# STM32U585xx register map
File version: 1.0
Registers are 32-bit, read-write, reset 0x0 unless marked. A register's access mark holds for its fields unless they carry their own. Offsets are from the block's base; [hi:lo] are bit positions; {n}, {i} and the like mark numbered series; 'fields as' and 'values as' point back to an identical list.

## RNG
Base 0x420C0800
Same registers: RNG_S 0x520C0800
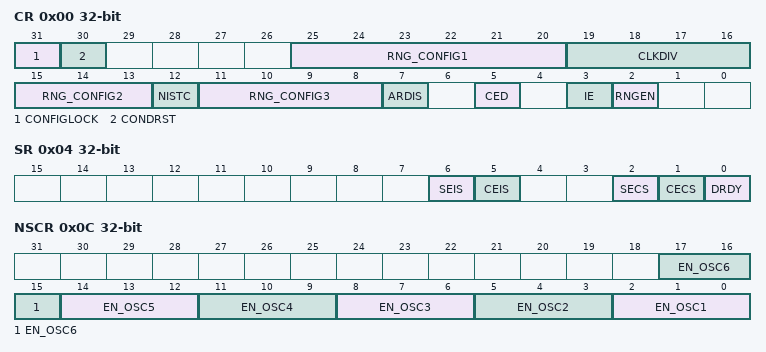
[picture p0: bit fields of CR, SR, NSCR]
0x00 CR — RNG control register
  [31] CONFIGLOCK
  [30] CONDRST
  [25:20] RNG_CONFIG1
  [19:16] CLKDIV
    0=BY_1 (No clock division); 1=BY_2 (2 RNG clock cycles per internal RNG clock); 2=BY_4 (4 RNG clock cycles per internal RNG clock); 3=BY_8 (8 RNG clock cycles per internal RNG clock); 4=BY_16 (16 RNG clock cycles per internal RNG clock); 5=BY_32 (32 RNG clock cycles per internal RNG clock); 6=BY_64 (64 RNG clock cycles per internal RNG clock); 7=BY_128 (128 RNG clock cycles per internal RNG clock); 8=BY_256 (256 RNG clock cycles per internal RNG clock); 9=BY_512 (512 RNG clock cycles per internal RNG clock); 10=BY_1024 (1024 RNG clock cycles per internal RNG clock); 11=BY_2048 (2048 RNG clock cycles per internal RNG clock); 12=BY_4096 (4096 RNG clock cycles per internal RNG clock); 13=BY_8192 (8192 RNG clock cycles per internal RNG clock); 14=BY_16384 (16384 RNG clock cycles per internal RNG clock); 15=BY_32768 (32768 RNG clock cycles per internal RNG clock)
  [15:13] RNG_CONFIG2
  [12] NISTC
  [11:8] RNG_CONFIG3
  [7] ARDIS
  [5] CED
  [3] IE
  [2] RNGEN
0x04 SR — RNG status register
  [6] SEIS, [5] CEIS, [2] SECS, [1] CECS, [0] DRDY
0x08 DR — RNG data register
0x0C NSCR — RNG noise source control register
  [3n-1:3n-3] EN_OSC{n} (n=1..6)
0x10 HTCR — RNG health test configuration register
  [31:0] HTCFG

## PKA
Base 0x420C2000
Same registers: PKA_S 0x520C2000
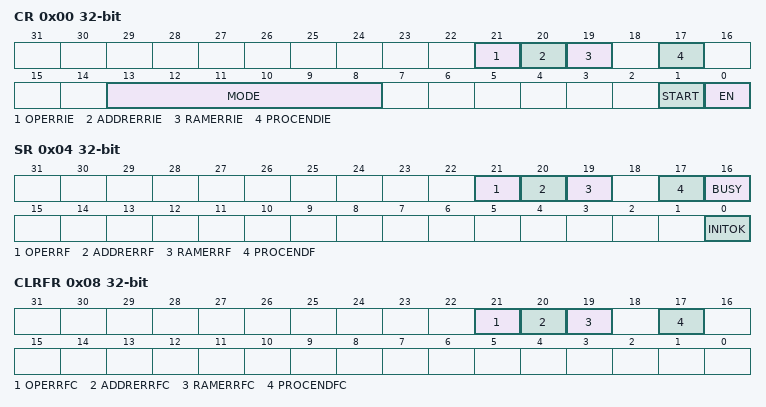
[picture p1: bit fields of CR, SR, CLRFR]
0x00 CR — PKA control register
  [21] OPERRIE — Operation Error interrupt enable
  [20] ADDRERRIE — Address error interrupt enable
  [19] RAMERRIE — RAM error interrupt enable
  [17] PROCENDIE — End of operation interrupt enable
  [13:8] MODE — MODE[5:0] PKA operation code
  [1] START — Start operation
  [0] EN — PKA enable
0x04 SR — PKA status register
  [21] OPERRF — PKA operation Error flag
  [20] ADDRERRF — Address error flag
  [19] RAMERRF — PKA RAM error flag
  [17] PROCENDF — PKA end of operation flag
  [16] BUSY — PKA operation is in progress
  [0] INITOK — PKA initialisation flag
0x08 CLRFR — PKA clear flag register
  [21] OPERRFC — Clear PKA operation Error flag
  [20] ADDRERRFC — Clear address error flag
  [19] RAMERRFC — Clear PKA RAM error flag
  [17] PROCENDFC — Clear PKA end of operation flag
{0x400+4i} RAM[{i}] (i=0..1333)

## OCTOSPIM — Serial Peripheral Interface IO Manager
Base 0x420C4000
Same registers: OCTOSPIM_S 0x520C4000
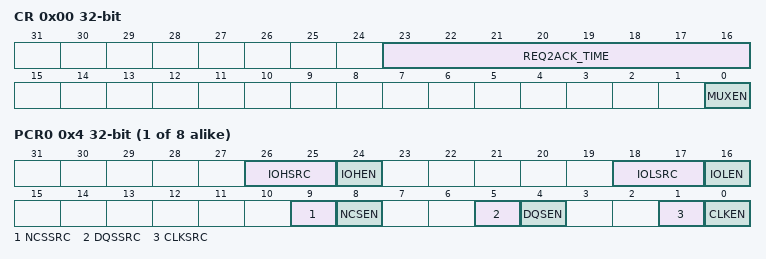
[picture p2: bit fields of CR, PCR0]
0x00 CR — OCTOSPIM IO Manager Control register
  [23:16] REQ2ACK_TIME — REQ to ACK Time
  [0] MUXEN — Multiplexed Mode Enable
{0x4+4i} PCR{i} (i=0..7) — OCTOSPIM IO Manager Port[1:8] Configuration register
  [26:25] IOHSRC — IO[7:4] Source for Port n
  [24] IOHEN — IO[7:4] Enable for Port n
  [18:17] IOLSRC — IO[3:0] Source for Port n
  [16] IOLEN — IO[3:0] Enable for Port n
  [9] NCSSRC — nCS Source for Port n
  [8] NCSEN — nCS Enable for Port n
  [5] DQSSRC — DQS Source for Port n
  [4] DQSEN — DQS Enable for Port n
  [1] CLKSRC — CLK/CLKn Source for Port n
  [0] CLKEN — CLK/CLKn Enable for Port n

## DLYB_SDMMC1 — Delay Block DLYB
Base 0x420C8400
Same registers: DLYB_SDMMC2 0x420C8800, DLYB_OCTOSPI1 0x420CF000, DLYB_OCTOSPI2 0x420CF400, DLYB_SDMMC1_S 0x520C8400, DLYB_SDMMC2_S 0x520C8800, DLYB_OCTOSPI1_S 0x520CF000, DLYB_OCTOSPI2_S 0x520CF400
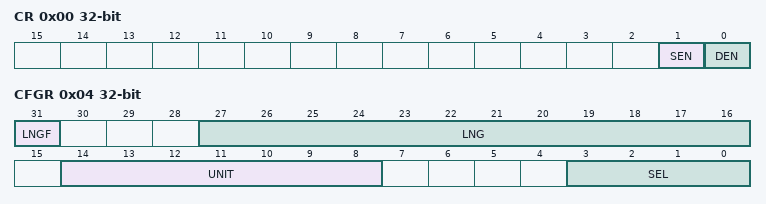
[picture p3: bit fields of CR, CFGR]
0x00 CR — DELAY BLOCK control register
  [1] SEN — Sampler length enable
  [0] DEN — Delay Block enable
0x04 CFGR — DELAY BLOCK configuration register
  [31] LNGF — Length valid flag
  [27:16] LNG — Delay line length value[11:0]
  [14:8] UNIT — Delay Defines the delay of a Unit delay cell[6:0]
  [3:0] SEL — Select the phase for the Output clock[3:0]

## FMC_Bank1_R — Flexible Memory Controller
Base 0x420D0400
Same registers: FMC_Bank1_R_S 0x520D0400
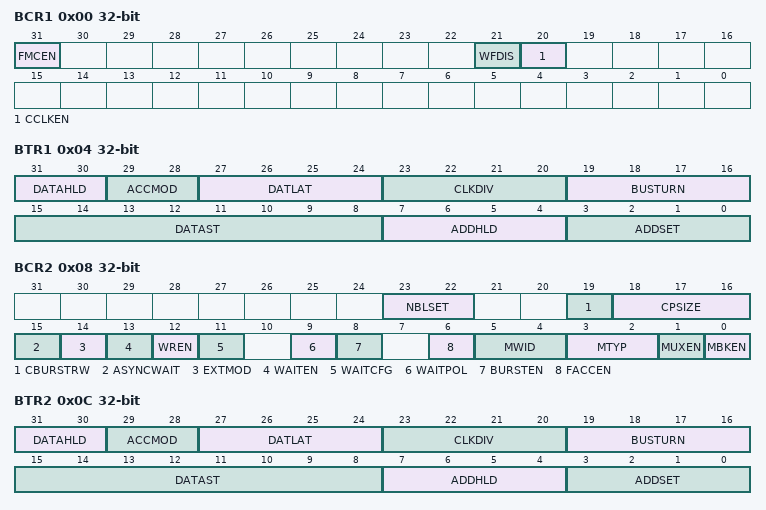
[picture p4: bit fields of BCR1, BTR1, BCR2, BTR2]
0x00 BCR1 — NOR/PSRAM chip-select control register(BCR) and chip-select timing register(BTR)
  [31] FMCEN — FMC controller Enable
  [21] WFDIS — Write FIFO Disable
  [20] CCLKEN — Continuous clock enable
0x04 BTR1 — NOR/PSRAM chip-select control register(BCR) and chip-select timing register(BTR)
  [31:30] DATAHLD — DATAHLD[1:0] bits (Data hold phase duration)
  [29:28] ACCMOD — ACCMOD[1:0] bits (Access mode)
  [27:24] DATLAT — DATLA[3:0] bits (Data latency)
  [23:20] CLKDIV — CLKDIV[3:0] bits (Clock divide ratio)
  [19:16] BUSTURN — BUSTURN[3:0] bits (Bus turnaround phase duration)
  [15:8] DATAST — DATAST [3:0] bits (Data-phase duration)
  [7:4] ADDHLD — ADDHLD[3:0] bits (Address-hold phase duration)
  [3:0] ADDSET — ADDSET[3:0] bits (Address setup phase duration)
0x08 BCR2 — NOR/PSRAM chip-select control register(BCR) and chip-select timing register(BTR)
  [23:22] NBLSET — Byte lane (NBL) setup
  [19] CBURSTRW — Write burst enable
  [18:16] CPSIZE — PSIZE[2:0] bits CRAM Page Size
  [15] ASYNCWAIT — Asynchronous wait
  [14] EXTMOD — Extended mode enable
  [13] WAITEN — Wait enable bit
  [12] WREN — Write enable bit
  [11] WAITCFG — Wait timing configuration
  [9] WAITPOL — Wait signal polarity bit
  [8] BURSTEN — Burst enable bit
  [6] FACCEN — Flash access enable
  [5:4] MWID — MWID[1:0] bits (Memory data bus width)
  [3:2] MTYP — MTYP[1:0] bits (Memory type)
  [1] MUXEN — Address/data multiplexing enable bit
  [0] MBKEN — Memory bank enable bit
0x0C BTR2 — NOR/PSRAM chip-select control register(BCR) and chip-select timing register(BTR)
  fields as BTR1
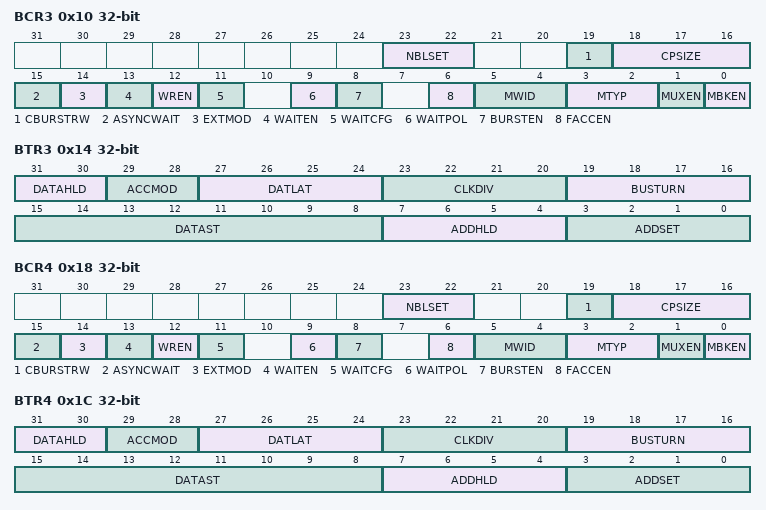
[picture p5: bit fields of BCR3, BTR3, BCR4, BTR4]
0x10 BCR3 — NOR/PSRAM chip-select control register(BCR) and chip-select timing register(BTR)
  fields as BCR2
0x14 BTR3 — NOR/PSRAM chip-select control register(BCR) and chip-select timing register(BTR)
  fields as BTR1
0x18 BCR4 — NOR/PSRAM chip-select control register(BCR) and chip-select timing register(BTR)
  fields as BCR2
0x1C BTR4 — NOR/PSRAM chip-select control register(BCR) and chip-select timing register(BTR)
  fields as BTR1
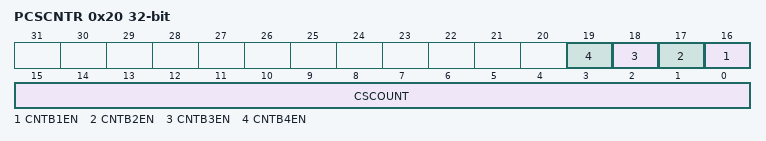
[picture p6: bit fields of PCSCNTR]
0x20 PCSCNTR — PSRAM chip-select counter register
  [n+15] CNTB{n}EN (n=1..4) — Counter PSRAM/NOR Bank1_{n} enable
  [15:0] CSCOUNT — CSCOUNT[15:0] bits (Chip select counter)
